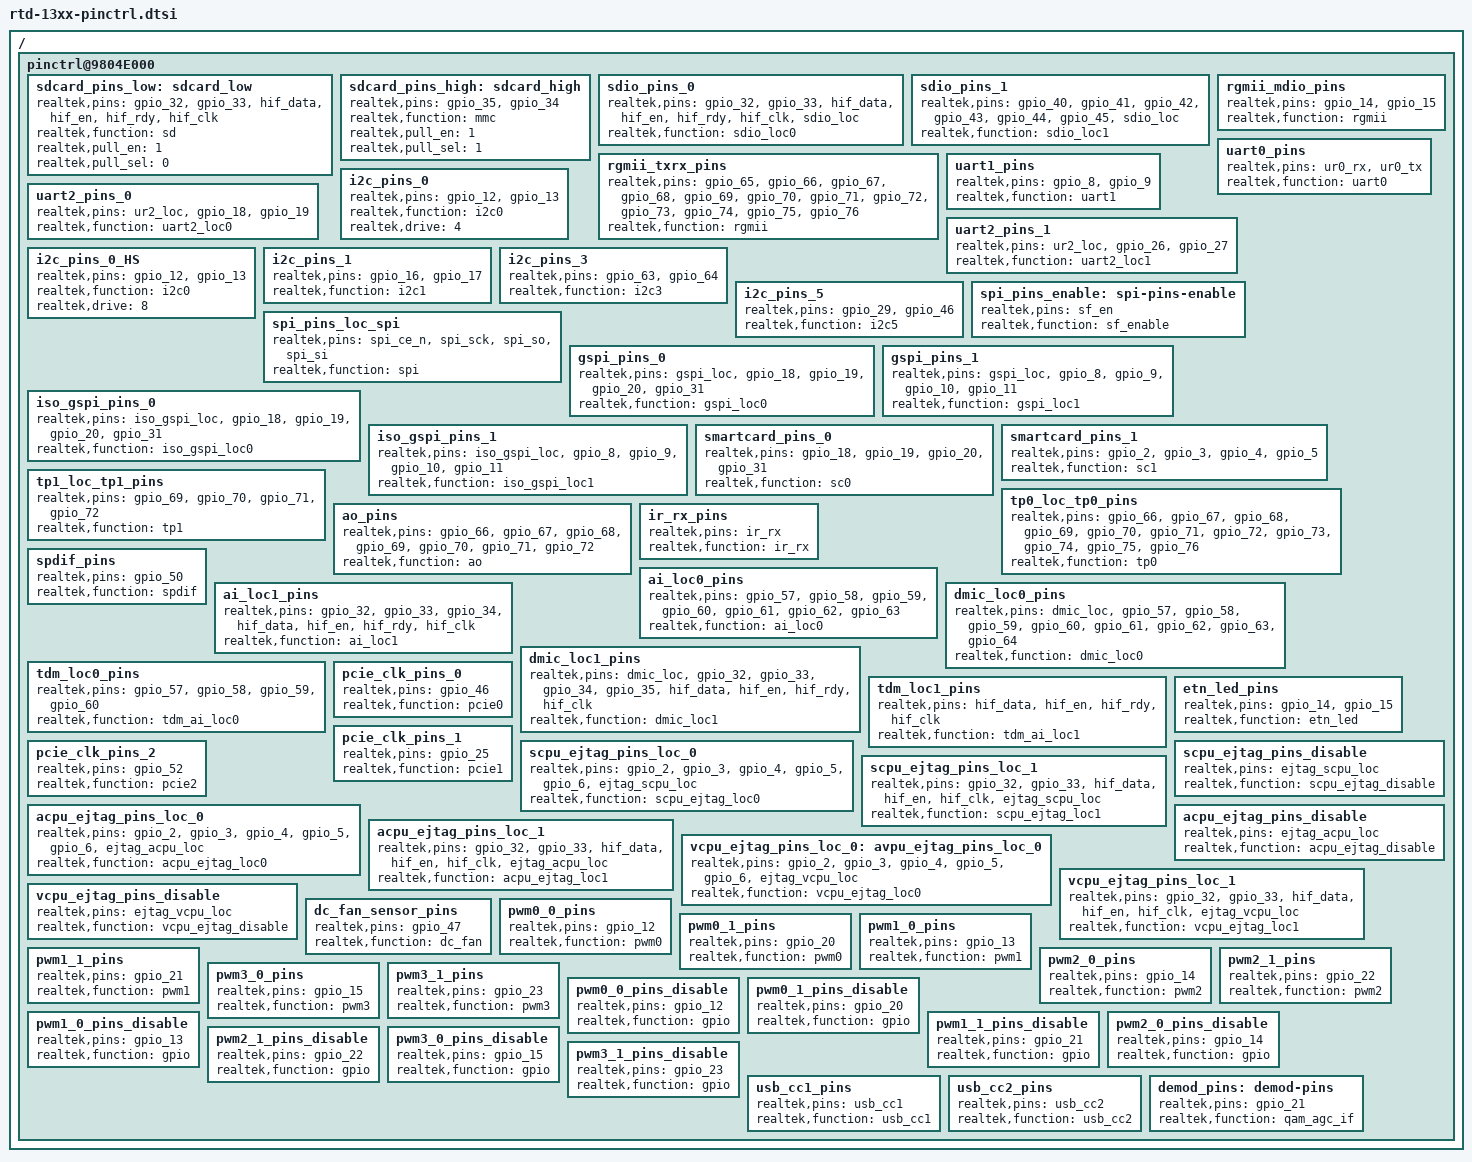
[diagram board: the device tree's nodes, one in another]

/ {
	pinctrl@9804E000 {
		sdcard_pins_low: sdcard_low {
			realtek,pins= "gpio_32",
			"gpio_33",
			"hif_data",
			"hif_en",
			"hif_rdy",
			"hif_clk";
			realtek,function="sd";
			realtek,pull_en = <1>;
			realtek,pull_sel = <0>;
		};

		sdcard_pins_high: sdcard_high {
			realtek,pins="gpio_35", "gpio_34";
			realtek,function="mmc";
			realtek,pull_en = <1>;
			realtek,pull_sel = <1>;
		};

		sdio_pins_0: sdio_pins_0 {
			realtek,pins= "gpio_32",
			"gpio_33",
			"hif_data",
			"hif_en",
			"hif_rdy",
			"hif_clk",
			"sdio_loc";
			realtek,function = "sdio_loc0";
		};

		sdio_pins_1: sdio_pins_1 {
			realtek,pins = "gpio_40",
			"gpio_41",
			"gpio_42",
			"gpio_43",
			"gpio_44",
			"gpio_45",
			"sdio_loc";
			realtek,function = "sdio_loc1";
		};

		rgmii_mdio_pins: rgmii_mdio_pins {
			realtek,pins = "gpio_14",
			"gpio_15";
			realtek,function = "rgmii";
		};

		rgmii_txrx_pins: rgmii_txrx_pins {
			realtek,pins = "gpio_65",
			"gpio_66",
			"gpio_67",
			"gpio_68",
			"gpio_69",
			"gpio_70",
			"gpio_71",
			"gpio_72",
			"gpio_73",
			"gpio_74",
			"gpio_75",
			"gpio_76";
			realtek,function = "rgmii";
		};

		uart0_pins: uart0_pins {
			realtek,pins = "ur0_rx",
			"ur0_tx";
			realtek,function = "uart0";
		};

		uart1_pins: uart1_pins {
			realtek,pins = "gpio_8",
			"gpio_9";
			realtek,function = "uart1";
		};

		uart2_pins_0: uart2_pins_0 {
			realtek,pins = "ur2_loc",
			"gpio_18",
			"gpio_19";
			realtek,function = "uart2_loc0";
		};

		uart2_pins_1: uart2_pins_1 {
			realtek,pins ="ur2_loc",
			"gpio_26",
			"gpio_27";
			realtek,function = "uart2_loc1";
		};

		i2c_pins_0: i2c_pins_0 {
			realtek,pins = "gpio_12",
			"gpio_13";
			realtek,function = "i2c0";
			realtek,drive = <4>;
		};

		i2c_pins_0_HS: i2c_pins_0_HS {
			realtek,pins = "gpio_12",
			"gpio_13";
			realtek,function = "i2c0";
			realtek,drive = <8>;
		};

		i2c_pins_1: i2c_pins_1 {
			realtek,pins = "gpio_16",
			"gpio_17";
			realtek,function = "i2c1";
		};


		i2c_pins_3: i2c_pins_3 {
			realtek,pins = "gpio_63",
			"gpio_64";
			realtek,function = "i2c3";
		};


		i2c_pins_5: i2c_pins_5 {
			realtek,pins = "gpio_29",
			"gpio_46";
			realtek,function = "i2c5";
		};

		spi_pins_enable: spi-pins-enable {
			realtek,pins = "sf_en";
			realtek,function = "sf_enable";
		};

		spi_pins_loc_spi: spi_pins_loc_spi {
			realtek,pins = "spi_ce_n",
			"spi_sck",
			"spi_so",
			"spi_si";
			realtek,function = "spi";
		};

		gspi_pins_0: gspi_pins_0 {
			realtek,pins = "gspi_loc",
			"gpio_18",
			"gpio_19",
			"gpio_20",
			"gpio_31";
			realtek,function = "gspi_loc0";
		};

		gspi_pins_1: gspi_pins_1 {
			realtek,pins = "gspi_loc",
			"gpio_8",
			"gpio_9",
			"gpio_10",
			"gpio_11";
			realtek,function = "gspi_loc1";
		};

		iso_gspi_pins_0: iso_gspi_pins_0 {
			realtek,pins = "iso_gspi_loc",
			"gpio_18",
			"gpio_19",
			"gpio_20",
			"gpio_31";
			realtek,function = "iso_gspi_loc0";
		};

		iso_gspi_pins_1: iso_gspi_pins_1 {
			realtek,pins = "iso_gspi_loc",
			"gpio_8",
			"gpio_9",
			"gpio_10",
			"gpio_11";
			realtek,function = "iso_gspi_loc1";
		};

		smartcard_pins_0:smartcard_pins_0{
			realtek,pins = "gpio_18",
			"gpio_19",
			"gpio_20",
			"gpio_31";
			realtek,function = "sc0";
		};

		smartcard_pins_1:smartcard_pins_1{
			realtek,pins = "gpio_2",
			"gpio_3",
			"gpio_4",
			"gpio_5";
			realtek,function = "sc1";
		};

		tp0_loc_tp0_pins: tp0_loc_tp0_pins {
			realtek,pins = "gpio_66",
			"gpio_67",
			"gpio_68",
			"gpio_69",
			"gpio_70",
			"gpio_71",
			"gpio_72",
			"gpio_73",
			"gpio_74",
			"gpio_75",
			"gpio_76";
			realtek,function = "tp0";
		};

		tp1_loc_tp1_pins: tp1_loc_tp1_pins {
			realtek,pins = "gpio_69",
			"gpio_70",
			"gpio_71",
			"gpio_72";
			realtek,function = "tp1";
		};

		ao_pins: ao_pins {
			realtek,pins = "gpio_66",
			"gpio_67",
			"gpio_68",
			"gpio_69",
			"gpio_70",
			"gpio_71",
			"gpio_72";
			realtek,function = "ao";
		};

		ir_rx_pins: ir_rx_pins {
			realtek,pins = "ir_rx";
			realtek,function = "ir_rx";
		};

		spdif_pins: spdif_pins {
			realtek,pins = "gpio_50";
			realtek,function = "spdif";
		};

		/*spdif_optical_pins: spdif_optical_pins {
			realtek,pins = "gpio_21", "gpio_68", "gpio_85";
			realtek,function = "spdif";
			realtek,pull_en =  <0>;
		};*/

		ai_loc0_pins: ai_loc0_pins {
			realtek,pins = "gpio_57",
				"gpio_58",
				"gpio_59",
				"gpio_60",
				"gpio_61",
				"gpio_62",
				"gpio_63";
			realtek,function = "ai_loc0";
		};

		ai_loc1_pins: ai_loc1_pins {
			realtek,pins = "gpio_32",
				"gpio_33",
				"gpio_34",
				"hif_data",
				"hif_en",
				"hif_rdy",
				"hif_clk";
			realtek,function = "ai_loc1";
		};

		dmic_loc0_pins: dmic_loc0_pins {
			realtek,pins = "dmic_loc",
				"gpio_57",
				"gpio_58",
				"gpio_59",
				"gpio_60",
				"gpio_61",
				"gpio_62",
				"gpio_63",
				"gpio_64";
			realtek,function = "dmic_loc0";
		};

		dmic_loc1_pins: dmic_loc1_pins {
			realtek,pins = "dmic_loc",
				"gpio_32",
				"gpio_33",
				"gpio_34",
				"gpio_35",
				"hif_data",
				"hif_en",
				"hif_rdy",
				"hif_clk";
			realtek,function = "dmic_loc1";
		};

		tdm_loc0_pins: tdm_loc0_pins {
			realtek,pins =
				"gpio_57",
				"gpio_58",
				"gpio_59",
				"gpio_60";
			realtek,function = "tdm_ai_loc0";
		};


		tdm_loc1_pins: tdm_loc1_pins {
			realtek,pins =
				"hif_data",
				"hif_en",
				"hif_rdy",
				"hif_clk";
			realtek,function = "tdm_ai_loc1";
		};


		/*i2s_out_4pins: i2s_out_4pins {
			realtek,pins ="tp_data_1",
			"tp_data_2",
			"tp_data_3",
			"tp_data_4";
			realtek,function = "ao";
		};*/

		/*i2s_in_pins: i2s_in_pins {
			realtek,pins = "gpio_6";
			realtek,function = "ai";
		};*/

		etn_led_pins: etn_led_pins {
			realtek,pins = "gpio_14",
			"gpio_15";
			realtek,function = "etn_led";
		};


		pcie_clk_pins_0: pcie_clk_pins_0 {
			realtek,pins = "gpio_46";
			realtek,function = "pcie0";
		};

		pcie_clk_pins_1: pcie_clk_pins_1 {
			realtek,pins = "gpio_25";
			realtek,function = "pcie1";
		};

		pcie_clk_pins_2: pcie_clk_pins_2 {
			realtek,pins = "gpio_52";
			realtek,function = "pcie2";
		};

		scpu_ejtag_pins_loc_0: scpu_ejtag_pins_loc_0 {
			realtek,pins = "gpio_2",
			"gpio_3",
			"gpio_4",
			"gpio_5",
			"gpio_6",
			"ejtag_scpu_loc";
			realtek,function = "scpu_ejtag_loc0";
		};

		scpu_ejtag_pins_loc_1: scpu_ejtag_pins_loc_1 {
			realtek,pins = "gpio_32",
			"gpio_33",
			"hif_data",
			"hif_en",
			"hif_clk",
			"ejtag_scpu_loc";
			realtek,function = "scpu_ejtag_loc1";
		};

		scpu_ejtag_pins_disable: scpu_ejtag_pins_disable {
			realtek,pins = "ejtag_scpu_loc";
			realtek,function = "scpu_ejtag_disable";
		};

		acpu_ejtag_pins_loc_0: acpu_ejtag_pins_loc_0 {
			realtek,pins = "gpio_2",
			"gpio_3",
			"gpio_4",
			"gpio_5",
			"gpio_6",
			"ejtag_acpu_loc";
			realtek,function = "acpu_ejtag_loc0";
		};

		acpu_ejtag_pins_loc_1: acpu_ejtag_pins_loc_1 {
			realtek,pins = "gpio_32",
			"gpio_33",
			"hif_data",
			"hif_en",
			"hif_clk",
			"ejtag_acpu_loc";
			realtek,function = "acpu_ejtag_loc1";
		};

		acpu_ejtag_pins_disable:acpu_ejtag_pins_disable{
			realtek,pins = "ejtag_acpu_loc";
			realtek,function = "acpu_ejtag_disable";
		};

		vcpu_ejtag_pins_loc_0: avpu_ejtag_pins_loc_0 {
			realtek,pins = "gpio_2",
			"gpio_3",
			"gpio_4",
			"gpio_5",
			"gpio_6",
			"ejtag_vcpu_loc";
			realtek,function = "vcpu_ejtag_loc0";
		};

		vcpu_ejtag_pins_loc_1: vcpu_ejtag_pins_loc_1 {
			realtek,pins = "gpio_32",
			"gpio_33",
			"hif_data",
			"hif_en",
			"hif_clk",
			"ejtag_vcpu_loc";
			realtek,function = "vcpu_ejtag_loc1";
		};

		vcpu_ejtag_pins_disable:vcpu_ejtag_pins_disable{
			realtek,pins = "ejtag_vcpu_loc";
			realtek,function = "vcpu_ejtag_disable";
		};

		dc_fan_sensor_pins: dc_fan_sensor_pins {
			realtek,pins = "gpio_47";
			realtek,function = "dc_fan";
		};

		pwm0_0_pins: pwm0_0_pins {
			realtek,pins = "gpio_12";
			realtek,function = "pwm0";
		};

		pwm0_1_pins: pwm0_1_pins {
			realtek,pins = "gpio_20";
			realtek,function = "pwm0";
		};

		pwm1_0_pins: pwm1_0_pins {
			realtek,pins = "gpio_13";
			realtek,function = "pwm1";
		};

		pwm1_1_pins: pwm1_1_pins {
			realtek,pins = "gpio_21";
			realtek,function = "pwm1";
		};

		pwm2_0_pins: pwm2_0_pins {
			realtek,pins = "gpio_14";
			realtek,function = "pwm2";
		};

		pwm2_1_pins: pwm2_1_pins {
			realtek,pins = "gpio_22";
			realtek,function = "pwm2";
		};

		pwm3_0_pins: pwm3_0_pins {
			realtek,pins = "gpio_15";
			realtek,function = "pwm3";
		};

		pwm3_1_pins: pwm3_1_pins {
			realtek,pins = "gpio_23";
			realtek,function = "pwm3";
		};

		pwm0_0_pins_disable: pwm0_0_pins_disable {
			realtek,pins = "gpio_12";
			realtek,function = "gpio";
		};

		pwm0_1_pins_disable: pwm0_1_pins_disable {
			realtek,pins = "gpio_20";
			realtek,function = "gpio";
		};

		pwm1_0_pins_disable: pwm1_0_pins_disable {
			realtek,pins = "gpio_13";
			realtek,function = "gpio";
		};

		pwm1_1_pins_disable: pwm1_1_pins_disable {
			realtek,pins = "gpio_21";
			realtek,function = "gpio";
		};

		pwm2_0_pins_disable: pwm2_0_pins_disable {
			realtek,pins = "gpio_14";
			realtek,function = "gpio";
		};

		pwm2_1_pins_disable: pwm2_1_pins_disable {
			realtek,pins = "gpio_22";
			realtek,function = "gpio";
		};

		pwm3_0_pins_disable: pwm3_0_pins_disable {
			realtek,pins = "gpio_15";
			realtek,function = "gpio";
		};

		pwm3_1_pins_disable: pwm3_1_pins_disable {
			realtek,pins = "gpio_23";
			realtek,function = "gpio";
		};

		usb_cc1_pins: usb_cc1_pins {
			realtek,pins = "usb_cc1";
			realtek,function = "usb_cc1";
		};

		usb_cc2_pins: usb_cc2_pins {
			realtek,pins = "usb_cc2";
			realtek,function = "usb_cc2";
		};

		demod_pins: demod-pins {
			realtek,pins = "gpio_21";
			realtek,function = "qam_agc_if";
		};

		/*rtc_pins: rtc_pins {
			realtek,pins = "gpio_25";
			realtek,function = "rtc";
		};*/

		/*prob0_pins: prob0_pins{
			realtek,pins = "prob_0";
	        realtek,function = "gpio";
		};

		prob1_pins: prob1_pins{
	        realtek,pins = "prob_1";
	        realtek,function = "gpio";
		};*/
	};
};

